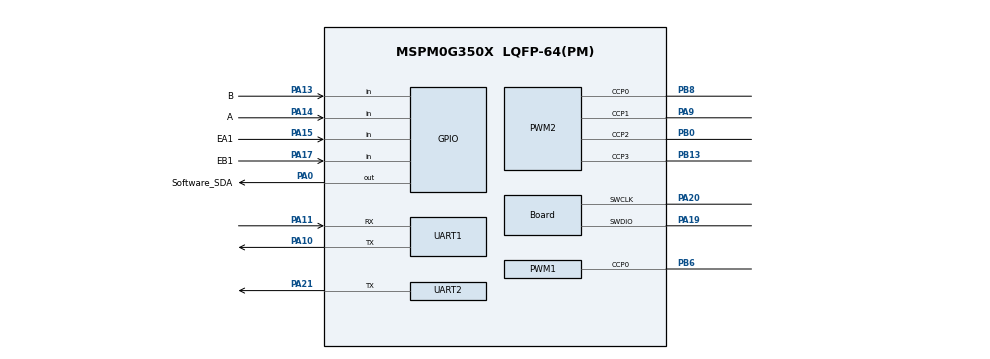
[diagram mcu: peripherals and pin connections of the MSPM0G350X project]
/**
 * @cliArgs --device "MSPM0G350X" --package "LQFP-64(PM)" --part "Default" --product "mspm0_sdk@2.01.00.03"
 * @versions {"tool":"1.20.0+3587"}
 */

/**
 * Import the modules used in this configuration.
 */
const ADC12         = scripting.addModule("/ti/driverlib/ADC12", {}, false);
const ADC121        = ADC12.addInstance();
const COMP          = scripting.addModule("/ti/driverlib/COMP", {}, false);
const COMP1         = COMP.addInstance();
const GPIO          = scripting.addModule("/ti/driverlib/GPIO", {}, false);
const GPIO1         = GPIO.addInstance();
const GPIO2         = GPIO.addInstance();
const GPIO3         = GPIO.addInstance();
const GPIO4         = GPIO.addInstance();
const GPIO5         = GPIO.addInstance();
const GPIO6         = GPIO.addInstance();
const GPIO7         = GPIO.addInstance();
const GPIO8         = GPIO.addInstance();
const GPIO9         = GPIO.addInstance();
const I2C           = scripting.addModule("/ti/driverlib/I2C", {}, false);
const I2C1          = I2C.addInstance();
const OPA           = scripting.addModule("/ti/driverlib/OPA", {}, false);
const OPA1          = OPA.addInstance();
const PWM           = scripting.addModule("/ti/driverlib/PWM", {}, false);
const PWM1          = PWM.addInstance();
const PWM2          = PWM.addInstance();
const SYSCTL        = scripting.addModule("/ti/driverlib/SYSCTL");
const TIMER         = scripting.addModule("/ti/driverlib/TIMER", {}, false);
const TIMER1        = TIMER.addInstance();
const UART          = scripting.addModule("/ti/driverlib/UART", {}, false);
const UART1         = UART.addInstance();
const UART2         = UART.addInstance();
const VREF          = scripting.addModule("/ti/driverlib/VREF");
const ProjectConfig = scripting.addModule("/ti/project_config/ProjectConfig");

/**
 * Write custom configuration values to the imported modules.
 */
ADC121.$name                      = "ADC12_0";
ADC121.sampClkDiv                 = "DL_ADC12_CLOCK_DIVIDE_8";
ADC121.enabledInterrupts          = ["DL_ADC12_INTERRUPT_MEM0_RESULT_LOADED"];
ADC121.adcMem0chansel             = "DL_ADC12_INPUT_CHAN_2";
ADC121.powerDownMode              = "DL_ADC12_POWER_DOWN_MODE_MANUAL";
ADC121.sampleTime0                = "125us";
ADC121.repeatMode                 = true;
ADC121.peripheral.$assign         = "ADC0";
ADC121.peripheral.adcPin2.$assign = "PA25";
ADC121.adcPin2Config.$name        = "AD";

const Board                       = scripting.addModule("/ti/driverlib/Board", {}, false);
Board.peripheral.$assign          = "DEBUGSS";
Board.peripheral.swclkPin.$assign = "PA20";
Board.peripheral.swdioPin.$assign = "PA19";

COMP1.$name              = "COMP_0";
COMP1.hysteresis         = "DL_COMP_HYSTERESIS_20";
COMP1.vSource            = "DL_COMP_REF_SOURCE_VDDA_DAC";
COMP1.terminalSelect     = "DL_COMP_REF_TERMINAL_SELECT_NEG";
COMP1.controlSelect      = "DL_COMP_DAC_CONTROL_SW";
COMP1.setDACCode0        = 0x4D;
COMP1.peripheral.$assign = "COMP0";

GPIO1.$name                          = "LED";
GPIO1.associatedPins.create(4);
GPIO1.associatedPins[0].$name        = "LEDR";
GPIO1.associatedPins[0].assignedPin  = "26";
GPIO1.associatedPins[0].assignedPort = "PORTB";
GPIO1.associatedPins[1].$name        = "LEDG";
GPIO1.associatedPins[1].assignedPort = "PORTB";
GPIO1.associatedPins[1].assignedPin  = "27";
GPIO1.associatedPins[2].$name        = "LEDB";
GPIO1.associatedPins[2].assignedPort = "PORTB";
GPIO1.associatedPins[2].assignedPin  = "22";
GPIO1.associatedPins[3].$name        = "PIN_0";
GPIO1.associatedPins[3].assignedPort = "PORTA";
GPIO1.associatedPins[3].assignedPin  = "12";
GPIO1.associatedPins[3].initialValue = "SET";

GPIO2.$name                          = "KEY";
GPIO2.associatedPins.create(2);
GPIO2.associatedPins[0].$name        = "KEY0";
GPIO2.associatedPins[0].assignedPort = "PORTA";
GPIO2.associatedPins[0].assignedPin  = "18";
GPIO2.associatedPins[0].direction    = "INPUT";
GPIO2.associatedPins[1].$name        = "KEY1";
GPIO2.associatedPins[1].assignedPort = "PORTB";
GPIO2.associatedPins[1].assignedPin  = "21";
GPIO2.associatedPins[1].direction    = "INPUT";

GPIO3.$name                          = "IIC";
GPIO3.associatedPins.create(2);
GPIO3.associatedPins[0].$name        = "SCL";
GPIO3.associatedPins[0].assignedPort = "PORTB";
GPIO3.associatedPins[0].assignedPin  = "14";
GPIO3.associatedPins[1].$name        = "SDA";
GPIO3.associatedPins[1].assignedPort = "PORTA";
GPIO3.associatedPins[1].assignedPin  = "30";

GPIO4.$name                          = "MYSPI";
GPIO4.associatedPins.create(6);
GPIO4.associatedPins[0].$name        = "MySPI_W_SCK";
GPIO4.associatedPins[0].assignedPort = "PORTB";
GPIO4.associatedPins[0].assignedPin  = "16";
GPIO4.associatedPins[1].$name        = "MySPI_W_MOSI";
GPIO4.associatedPins[1].assignedPort = "PORTB";
GPIO4.associatedPins[1].assignedPin  = "7";
GPIO4.associatedPins[2].$name        = "MySPI_R_MISO";
GPIO4.associatedPins[2].assignedPort = "PORTB";
GPIO4.associatedPins[2].assignedPin  = "15";
GPIO4.associatedPins[3].$name        = "MySPI_W_SS";
GPIO4.associatedPins[3].assignedPort = "PORTA";
GPIO4.associatedPins[3].assignedPin  = "29";
GPIO4.associatedPins[4].$name        = "OLED_RES";
GPIO4.associatedPins[4].assignedPort = "PORTB";
GPIO4.associatedPins[4].assignedPin  = "17";
GPIO4.associatedPins[5].$name        = "OLED_DC";
GPIO4.associatedPins[5].assignedPort = "PORTB";
GPIO4.associatedPins[5].assignedPin  = "1";

GPIO5.$name                          = "BT6612";
GPIO5.associatedPins.create(8);
GPIO5.associatedPins[0].$name        = "AIN1";
GPIO5.associatedPins[0].initialValue = "SET";
GPIO5.associatedPins[0].ioStructure  = "SD";
GPIO5.associatedPins[0].assignedPort = "PORTA";
GPIO5.associatedPins[0].assignedPin  = "27";
GPIO5.associatedPins[1].$name        = "AIN2";
GPIO5.associatedPins[1].initialValue = "SET";
GPIO5.associatedPins[1].ioStructure  = "SD";
GPIO5.associatedPins[1].assignedPort = "PORTA";
GPIO5.associatedPins[1].assignedPin  = "26";
GPIO5.associatedPins[2].$name        = "AIN3";
GPIO5.associatedPins[2].initialValue = "SET";
GPIO5.associatedPins[2].ioStructure  = "SD";
GPIO5.associatedPins[2].assignedPort = "PORTB";
GPIO5.associatedPins[2].assignedPin  = "24";
GPIO5.associatedPins[3].$name        = "AIN4";
GPIO5.associatedPins[3].initialValue = "SET";
GPIO5.associatedPins[3].ioStructure  = "SD";
GPIO5.associatedPins[3].assignedPort = "PORTB";
GPIO5.associatedPins[3].assignedPin  = "23";
GPIO5.associatedPins[4].$name        = "BIN1";
GPIO5.associatedPins[4].initialValue = "SET";
GPIO5.associatedPins[4].ioStructure  = "SD";
GPIO5.associatedPins[4].assignedPort = "PORTA";
GPIO5.associatedPins[4].assignedPin  = "4";
GPIO5.associatedPins[5].$name        = "BIN2";
GPIO5.associatedPins[5].initialValue = "SET";
GPIO5.associatedPins[5].ioStructure  = "SD";
GPIO5.associatedPins[5].assignedPort = "PORTA";
GPIO5.associatedPins[5].assignedPin  = "5";
GPIO5.associatedPins[6].$name        = "BIN3";
GPIO5.associatedPins[6].initialValue = "SET";
GPIO5.associatedPins[6].ioStructure  = "SD";
GPIO5.associatedPins[6].assignedPort = "PORTB";
GPIO5.associatedPins[6].assignedPin  = "10";
GPIO5.associatedPins[7].$name        = "BIN_4";
GPIO5.associatedPins[7].initialValue = "SET";
GPIO5.associatedPins[7].ioStructure  = "SD";
GPIO5.associatedPins[7].assignedPort = "PORTB";
GPIO5.associatedPins[7].assignedPin  = "11";

GPIO6.$name                          = "xunji";
GPIO6.associatedPins.create(5);
GPIO6.associatedPins[0].$name        = "A1";
GPIO6.associatedPins[0].direction    = "INPUT";
GPIO6.associatedPins[0].assignedPort = "PORTB";
GPIO6.associatedPins[0].assignedPin  = "18";
GPIO6.associatedPins[1].$name        = "A2";
GPIO6.associatedPins[1].direction    = "INPUT";
GPIO6.associatedPins[1].ioStructure  = "SD";
GPIO6.associatedPins[1].assignedPort = "PORTA";
GPIO6.associatedPins[1].assignedPin  = "3";
GPIO6.associatedPins[2].$name        = "A3";
GPIO6.associatedPins[2].direction    = "INPUT";
GPIO6.associatedPins[2].ioStructure  = "SD";
GPIO6.associatedPins[2].assignedPort = "PORTB";
GPIO6.associatedPins[2].assignedPin  = "4";
GPIO6.associatedPins[3].$name        = "A4";
GPIO6.associatedPins[3].direction    = "INPUT";
GPIO6.associatedPins[3].ioStructure  = "SD";
GPIO6.associatedPins[3].assignedPort = "PORTB";
GPIO6.associatedPins[3].assignedPin  = "3";
GPIO6.associatedPins[4].$name        = "A5";
GPIO6.associatedPins[4].direction    = "INPUT";
GPIO6.associatedPins[4].ioStructure  = "SD";
GPIO6.associatedPins[4].assignedPin  = "6";
GPIO6.associatedPins[4].assignedPort = "PORTA";

GPIO7.$name                         = "Encoder";
GPIO7.associatedPins.create(4);
GPIO7.associatedPins[0].$name       = "A";
GPIO7.associatedPins[0].direction   = "INPUT";
GPIO7.associatedPins[0].interruptEn = true;
GPIO7.associatedPins[0].polarity    = "RISE";
GPIO7.associatedPins[0].pin.$assign = "PA14";
GPIO7.associatedPins[1].$name       = "B";
GPIO7.associatedPins[1].direction   = "INPUT";
GPIO7.associatedPins[1].interruptEn = true;
GPIO7.associatedPins[1].polarity    = "RISE";
GPIO7.associatedPins[1].pin.$assign = "PA13";
GPIO7.associatedPins[2].$name       = "EA1";
GPIO7.associatedPins[2].direction   = "INPUT";
GPIO7.associatedPins[2].interruptEn = true;
GPIO7.associatedPins[2].polarity    = "RISE";
GPIO7.associatedPins[2].pin.$assign = "PA15";
GPIO7.associatedPins[3].$name       = "EB1";
GPIO7.associatedPins[3].direction   = "INPUT";
GPIO7.associatedPins[3].interruptEn = true;
GPIO7.associatedPins[3].polarity    = "RISE";
GPIO7.associatedPins[3].pin.$assign = "PA17";

GPIO8.$name                         = "HC_SR04";
GPIO8.associatedPins.create(2);
GPIO8.associatedPins[0].$name       = "ECHO";
GPIO8.associatedPins[0].direction   = "INPUT";
GPIO8.associatedPins[0].interruptEn = true;
GPIO8.associatedPins[0].polarity    = "RISE_FALL";
GPIO8.associatedPins[0].assignedPin = "20";
GPIO8.associatedPins[1].$name       = "TRIG";
GPIO8.associatedPins[1].assignedPin = "19";

GPIO9.$name                          = "MPU";
GPIO9.associatedPins.create(2);
GPIO9.associatedPins[0].$name        = "Software_SDA";
GPIO9.associatedPins[0].initialValue = "SET";
GPIO9.associatedPins[0].ioStructure  = "OD";
GPIO9.associatedPins[0].pin.$assign  = "PA0";
GPIO9.associatedPins[1].$name        = "Software_SCL";
GPIO9.associatedPins[1].initialValue = "SET";
GPIO9.associatedPins[1].ioStructure  = "OD";

I2C1.basicEnableController             = true;
I2C1.basicControllerStandardBusSpeed   = "Fast";
I2C1.$name                             = "I2C_1";
I2C1.peripheral.$assign                = "I2C1";
I2C1.sdaPinConfig.hideOutputInversion  = scripting.forceWrite(false);
I2C1.sdaPinConfig.onlyInternalResistor = scripting.forceWrite(false);
I2C1.sdaPinConfig.passedPeripheralType = scripting.forceWrite("Digital");
I2C1.sdaPinConfig.$name                = "ti_driverlib_gpio_GPIOPinGeneric2";
I2C1.sclPinConfig.hideOutputInversion  = scripting.forceWrite(false);
I2C1.sclPinConfig.onlyInternalResistor = scripting.forceWrite(false);
I2C1.sclPinConfig.passedPeripheralType = scripting.forceWrite("Digital");
I2C1.sclPinConfig.$name                = "ti_driverlib_gpio_GPIOPinGeneric3";

OPA1.$name              = "OPA_0";
OPA1.cfg0OutputPin      = "ENABLED";
OPA1.cfg0PSELChannel    = "DAC8_OUT";
OPA1.cfg0NSELChannel    = "RTOP";
OPA1.advBW              = "HIGH";
OPA1.OutPinConfig.$name = "o";

PWM1.$name                              = "Sever";
PWM1.ccIndex                            = [0];
PWM1.clockDivider                       = 4;
PWM1.timerCount                         = 20000;
PWM1.clockPrescale                      = 8;
PWM1.peripheral.ccp0Pin.$assign         = "PB6";
PWM1.PWM_CHANNEL_0.$name                = "ti_driverlib_pwm_PWMTimerCC0";
PWM1.ccp0PinConfig.direction            = scripting.forceWrite("OUTPUT");
PWM1.ccp0PinConfig.hideOutputInversion  = scripting.forceWrite(false);
PWM1.ccp0PinConfig.onlyInternalResistor = scripting.forceWrite(false);
PWM1.ccp0PinConfig.passedPeripheralType = scripting.forceWrite("Digital");
PWM1.ccp0PinConfig.$name                = "sever";

PWM2.$name                              = "Motor";
PWM2.ccIndex                            = [0,1,2,3];
PWM2.timerCount                         = 3200;
PWM2.pwmMode                            = "EDGE_ALIGN_UP";
PWM2.peripheral.$assign                 = "TIMA0";
PWM2.peripheral.ccp0Pin.$assign         = "PB8";
PWM2.peripheral.ccp1Pin.$assign         = "PA9";
PWM2.peripheral.ccp2Pin.$assign         = "PB0";
PWM2.peripheral.ccp3Pin.$assign         = "PB13";
PWM2.PWM_CHANNEL_0.$name                = "ti_driverlib_pwm_PWMTimerCC1";
PWM2.PWM_CHANNEL_0.ccValue              = 3199;
PWM2.PWM_CHANNEL_1.$name                = "ti_driverlib_pwm_PWMTimerCC2";
PWM2.PWM_CHANNEL_1.ccValue              = 3199;
PWM2.ccp0PinConfig.direction            = scripting.forceWrite("OUTPUT");
PWM2.ccp0PinConfig.hideOutputInversion  = scripting.forceWrite(false);
PWM2.ccp0PinConfig.onlyInternalResistor = scripting.forceWrite(false);
PWM2.ccp0PinConfig.passedPeripheralType = scripting.forceWrite("Digital");
PWM2.ccp0PinConfig.$name                = "c";
PWM2.ccp1PinConfig.direction            = scripting.forceWrite("OUTPUT");
PWM2.ccp1PinConfig.hideOutputInversion  = scripting.forceWrite(false);
PWM2.ccp1PinConfig.onlyInternalResistor = scripting.forceWrite(false);
PWM2.ccp1PinConfig.passedPeripheralType = scripting.forceWrite("Digital");
PWM2.ccp1PinConfig.$name                = "d";
PWM2.PWM_CHANNEL_2.$name                = "ti_driverlib_pwm_PWMTimerCC3";
PWM2.PWM_CHANNEL_3.$name                = "ti_driverlib_pwm_PWMTimerCC4";
PWM2.PWM_CHANNEL_3.ccValue              = 3199;
PWM2.ccp2PinConfig.$name                = "a";
PWM2.ccp3PinConfig.$name                = "ti_driverlib_gpio_GPIOPinGeneric4";

SYSCTL.clockTreeEn = true;

TIMER1.$name            = "TIMER_0";
TIMER1.timerMode        = "PERIODIC_UP";
TIMER1.timerPeriod      = "20ms";
TIMER1.timerStartTimer  = true;
TIMER1.timerClkPrescale = 100;
TIMER1.interrupts       = ["ZERO"];

UART1.$name                    = "UART_0";
UART1.txFifoThreshold          = "DL_UART_TX_FIFO_LEVEL_1_4_EMPTY";
UART1.enabledInterrupts        = ["OVERRUN_ERROR","RX"];
UART1.targetBaudRate           = 115200;
UART1.peripheral.rxPin.$assign = "PA11";
UART1.peripheral.txPin.$assign = "PA10";
UART1.txPinConfig.$name        = "ti_driverlib_gpio_GPIOPinGeneric0";
UART1.rxPinConfig.$name        = "ti_driverlib_gpio_GPIOPinGeneric1";

UART2.$name                    = "UART_1";
UART2.enabledInterrupts        = ["RX"];
UART2.peripheral.txPin.$assign = "PA21";
UART2.txPinConfig.$name        = "ti_driverlib_gpio_GPIOPinGeneric0_COPY";
UART2.rxPinConfig.$name        = "ti_driverlib_gpio_GPIOPinGeneric1_COPY";

VREF.checkVREFReady         = true;
VREF.basicIntVolt           = "DL_VREF_BUFCONFIG_OUTPUT_2_5V";
VREF.vrefPosPinConfig.$name = "v";

ProjectConfig.deviceSpin = "MSPM0G3507";
scripting.suppress("Migrating requires going through the Switch Board or Device menu in the Device View section\\.", ProjectConfig, "deviceSpin");

/**
 * Pinmux solution for unlocked pins/peripherals. This ensures that minor changes to the automatic solver in a future
 * version of the tool will not impact the pinmux you originally saw.  These lines can be completely deleted in order to
 * re-solve from scratch.
 */
GPIO1.associatedPins[0].pin.$suggestSolution = "PB26";
GPIO1.associatedPins[1].pin.$suggestSolution = "PB27";
GPIO1.associatedPins[2].pin.$suggestSolution = "PB22";
GPIO1.associatedPins[3].pin.$suggestSolution = "PA12";
GPIO2.associatedPins[0].pin.$suggestSolution = "PA18";
GPIO2.associatedPins[1].pin.$suggestSolution = "PB21";
GPIO3.associatedPins[0].pin.$suggestSolution = "PB14";
GPIO3.associatedPins[1].pin.$suggestSolution = "PA30";
GPIO4.associatedPins[0].pin.$suggestSolution = "PB16";
GPIO4.associatedPins[1].pin.$suggestSolution = "PB7";
GPIO4.associatedPins[2].pin.$suggestSolution = "PB15";
GPIO4.associatedPins[3].pin.$suggestSolution = "PA29";
GPIO4.associatedPins[4].pin.$suggestSolution = "PB17";
GPIO4.associatedPins[5].pin.$suggestSolution = "PB1";
GPIO5.associatedPins[0].pin.$suggestSolution = "PA27";
GPIO5.associatedPins[1].pin.$suggestSolution = "PA26";
GPIO5.associatedPins[2].pin.$suggestSolution = "PB24";
GPIO5.associatedPins[3].pin.$suggestSolution = "PB23";
GPIO5.associatedPins[4].pin.$suggestSolution = "PA4";
GPIO5.associatedPins[5].pin.$suggestSolution = "PA5";
GPIO5.associatedPins[6].pin.$suggestSolution = "PB10";
GPIO5.associatedPins[7].pin.$suggestSolution = "PB11";
GPIO6.associatedPins[0].pin.$suggestSolution = "PB18";
GPIO6.associatedPins[1].pin.$suggestSolution = "PA3";
GPIO6.associatedPins[2].pin.$suggestSolution = "PB4";
GPIO6.associatedPins[3].pin.$suggestSolution = "PB3";
GPIO6.associatedPins[4].pin.$suggestSolution = "PA6";
GPIO8.associatedPins[0].pin.$suggestSolution = "PB20";
GPIO8.associatedPins[1].pin.$suggestSolution = "PB19";
GPIO9.associatedPins[1].pin.$suggestSolution = "PA1";
I2C1.peripheral.sdaPin.$suggestSolution      = "PA16";
I2C1.peripheral.sclPin.$suggestSolution      = "PB2";
OPA1.peripheral.$suggestSolution             = "OPA0";
OPA1.peripheral.OutPin.$suggestSolution      = "PA22";
PWM1.peripheral.$suggestSolution             = "TIMG6";
TIMER1.peripheral.$suggestSolution           = "TIMA1";
UART1.peripheral.$suggestSolution            = "UART0";
UART2.peripheral.$suggestSolution            = "UART2";
UART2.peripheral.rxPin.$suggestSolution      = "PA24";
VREF.peripheral.$suggestSolution             = "VREF";
VREF.peripheral.vrefPosPin.$suggestSolution  = "PA23";
